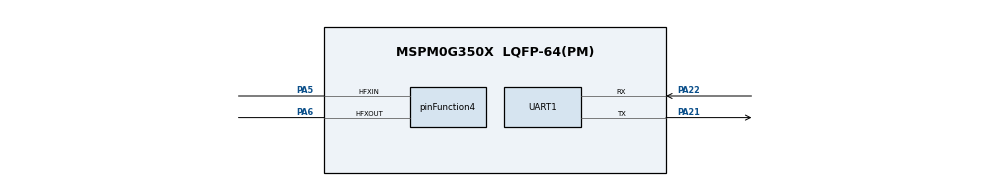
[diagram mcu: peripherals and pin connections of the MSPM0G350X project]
/**
 * @cliArgs --device "MSPM0G350X" --part "Default" --package "LQFP-64(PM)" --product "mspm0_sdk@2.03.00.07"
 * @versions {"tool":"1.23.0+4000"}
 */

const SYSCTL        = scripting.addModule("/ti/driverlib/SYSCTL");
const UART          = scripting.addModule("/ti/driverlib/UART", {}, false);
const UART1         = UART.addInstance();
const ProjectConfig = scripting.addModule("/ti/project_config/ProjectConfig");

const divider2       = system.clockTree["HFCLK4MFPCLKDIV"];
divider2.divideValue = 10;

const divider6       = system.clockTree["PLL_CLK2X_DIV"];
divider6.divideValue = 4;

const divider9       = system.clockTree["UDIV"];
divider9.divideValue = 2;

const gate7  = system.clockTree["MFCLKGATE"];
gate7.enable = true;

const gate8  = system.clockTree["MFPCLKGATE"];
gate8.enable = true;

const multiplier2         = system.clockTree["PLL_QDIV"];
multiplier2.multiplyValue = 4;

const mux4       = system.clockTree["EXHFMUX"];
mux4.inputSelect = "EXHFMUX_XTAL";

const mux8       = system.clockTree["HSCLKMUX"];
mux8.inputSelect = "HSCLKMUX_SYSPLL0";

const mux10       = system.clockTree["MFPCLKMUX"];
mux10.inputSelect = "MFPCLKMUX_HFCLK";

const mux12       = system.clockTree["SYSPLLMUX"];
mux12.inputSelect = "zSYSPLLMUX_HFCLK";

const pinFunction4                        = system.clockTree["HFXT"];
pinFunction4.inputFreq                    = 40;
pinFunction4.enable                       = true;
pinFunction4.HFCLKMonitor                 = true;
pinFunction4.HFXTStartup                  = 20;
pinFunction4.peripheral.$assign           = "SYSCTL";
pinFunction4.peripheral.hfxInPin.$assign  = "PA5";
pinFunction4.peripheral.hfxOutPin.$assign = "PA6";

SYSCTL.validateClkStatus     = true;
SYSCTL.HFCLKSource           = "HFXT";
SYSCTL.waitState             = "1";
SYSCTL.enableSYSOSCFCL       = true;
SYSCTL.enableROSC            = true;
SYSCTL.forceDefaultClkConfig = true;
SYSCTL.clockTreeEn           = true;

UART1.$name                            = "UART_OUT";
UART1.uartClkSrc                       = "BUSCLK";
UART1.targetBaudRate                   = 921600;
UART1.peripheral.$assign               = "UART2";
UART1.peripheral.rxPin.$assign         = "PA22";
UART1.peripheral.txPin.$assign         = "PA21";
UART1.txPinConfig.$name                = "ti_driverlib_gpio_GPIOPinGeneric3";
UART1.txPinConfig.direction            = scripting.forceWrite("OUTPUT");
UART1.txPinConfig.hideOutputInversion  = scripting.forceWrite(false);
UART1.txPinConfig.onlyInternalResistor = scripting.forceWrite(false);
UART1.txPinConfig.passedPeripheralType = scripting.forceWrite("Digital");
UART1.rxPinConfig.$name                = "ti_driverlib_gpio_GPIOPinGeneric4";
UART1.rxPinConfig.hideOutputInversion  = scripting.forceWrite(false);
UART1.rxPinConfig.onlyInternalResistor = scripting.forceWrite(false);
UART1.rxPinConfig.passedPeripheralType = scripting.forceWrite("Digital");

ProjectConfig.deviceSpin  = "MSPM0G3507";
ProjectConfig.genLibCMSIS = true;
